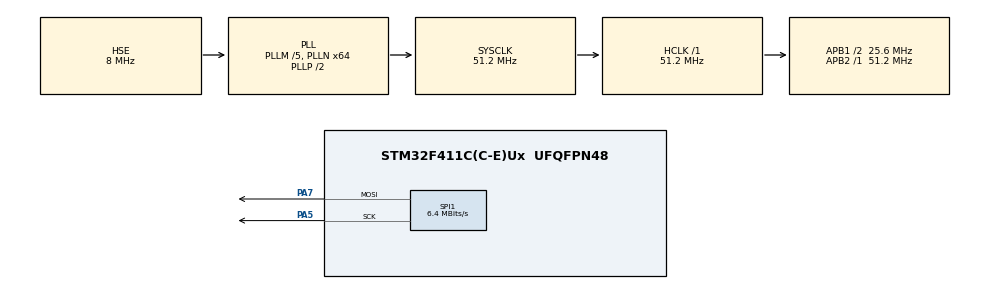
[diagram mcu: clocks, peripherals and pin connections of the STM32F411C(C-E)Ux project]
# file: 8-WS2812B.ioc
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Mcu.Family=STM32F4
Mcu.Name=STM32F411C(C-E)Ux
Mcu.Package=UFQFPN48
NVIC.PriorityGroup=NVIC_PRIORITYGROUP_4
PA13.Mode=Serial-Wire
PA13.Signal=SYS_JTMS-SWDIO
PA14.Mode=Serial-Wire
PA14.Signal=SYS_JTCK-SWCLK
PA5.Mode=TX_Only_Simplex_Unidirect_Master
PA5.Signal=SPI1_SCK
PA7.Mode=TX_Only_Simplex_Unidirect_Master
PA7.Signal=SPI1_MOSI
PC14-OSC32_IN.Mode=LSE-External-Oscillator
PC14-OSC32_IN.Signal=RCC_OSC32_IN
PC15-OSC32_OUT.Mode=LSE-External-Oscillator
PC15-OSC32_OUT.Signal=RCC_OSC32_OUT
PH0\ -\ OSC_IN.Mode=HSE-External-Oscillator
PH0\ -\ OSC_IN.Signal=RCC_OSC_IN
PH1\ -\ OSC_OUT.Mode=HSE-External-Oscillator
PH1\ -\ OSC_OUT.Signal=RCC_OSC_OUT
ProjectManager.HeapSize=0x200
ProjectManager.StackSize=0x400
ProjectManager.TargetToolchain=SW4STM32
RCC.48MHZClocksFreq_Value=25600000
RCC.AHBFreq_Value=51200000
RCC.APB1CLKDivider=RCC_HCLK_DIV2
RCC.APB1Freq_Value=25600000
RCC.APB1TimFreq_Value=51200000
RCC.APB2Freq_Value=51200000
RCC.APB2TimFreq_Value=51200000
RCC.CortexFreq_Value=51200000
RCC.HCLKFreq_Value=51200000
RCC.HSE_VALUE=8000000
RCC.HSI_VALUE=16000000
RCC.PLLM=5
RCC.PLLN=64
RCC.PLLSourceVirtual=RCC_PLLSOURCE_HSE
RCC.SYSCLKFreq_VALUE=51200000
RCC.SYSCLKSource=RCC_SYSCLKSOURCE_PLLCLK
RCC.VCOOutputFreq_Value=102400000
SPI1.BaudRatePrescaler=SPI_BAUDRATEPRESCALER_8
SPI1.CLKPolarity=SPI_POLARITY_LOW
SPI1.CalculateBaudRate=6.4 MBits/s
SPI1.DataSize=SPI_DATASIZE_8BIT
SPI1.Mode=SPI_MODE_MASTER
board=8-WS2812B

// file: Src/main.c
/**
 ******************************************************************************
 * File Name          : main.c
 * Description        : Main program body
 ******************************************************************************
 *
 * COPYRIGHT(c) 2016 STMicroelectronics
 *
 * Redistribution and use in source and binary forms, with or without modification,
 * are permitted provided that the following conditions are met:
 *   1. Redistributions of source code must retain the above copyright notice,
 *      this list of conditions and the following disclaimer.
 *   2. Redistributions in binary form must reproduce the above copyright notice,
 *      this list of conditions and the following disclaimer in the documentation
 *      and/or other materials provided with the distribution.
 *   3. Neither the name of STMicroelectronics nor the names of its contributors
 *      may be used to endorse or promote products derived from this software
 *      without specific prior written permission.
 *
 * THIS SOFTWARE IS PROVIDED BY THE COPYRIGHT HOLDERS AND CONTRIBUTORS "AS IS"
 * AND ANY EXPRESS OR IMPLIED WARRANTIES, INCLUDING, BUT NOT LIMITED TO, THE
 * IMPLIED WARRANTIES OF MERCHANTABILITY AND FITNESS FOR A PARTICULAR PURPOSE ARE
 * DISCLAIMED. IN NO EVENT SHALL THE COPYRIGHT HOLDER OR CONTRIBUTORS BE LIABLE
 * FOR ANY DIRECT, INDIRECT, INCIDENTAL, SPECIAL, EXEMPLARY, OR CONSEQUENTIAL
 * DAMAGES (INCLUDING, BUT NOT LIMITED TO, PROCUREMENT OF SUBSTITUTE GOODS OR
 * SERVICES; LOSS OF USE, DATA, OR PROFITS; OR BUSINESS INTERRUPTION) HOWEVER
 * CAUSED AND ON ANY THEORY OF LIABILITY, WHETHER IN CONTRACT, STRICT LIABILITY,
 * OR TORT (INCLUDING NEGLIGENCE OR OTHERWISE) ARISING IN ANY WAY OUT OF THE USE
 * OF THIS SOFTWARE, EVEN IF ADVISED OF THE POSSIBILITY OF SUCH DAMAGE.
 *
 ******************************************************************************
 */
#include "stm32f4xx_hal.h"
#include "spi.h"
#include "gpio.h"

/* USER CODE BEGIN Includes */
#include "ws2812b.h"
#include "lighting.h"
/* USER CODE END Includes */

/* USER CODE BEGIN PV */
/* Private variables ---------------------------------------------------------*/

/* USER CODE END PV */

void SystemClock_Config(void);

/* USER CODE BEGIN PFP */
/* Private function prototypes -----------------------------------------------*/

/* USER CODE END PFP */

int main(void) {

	/* MCU Configuration----------------------------------------------------------*/

	/* Reset of all peripherals, Initializes the Flash interface and the Systick. */
	HAL_Init();

	/* Configure the system clock */
	SystemClock_Config();

	/* Initialize all configured peripherals */
	MX_GPIO_Init();
	MX_SPI1_Init();

	/* USER CODE BEGIN 2 */
	ws2812b_config led_strip_c = ws2812b_init(&hspi1, 30);
	lighting_config l_c = lighting_init(30);

	lighting_hsv from_color, to_color;

	from_color.hue = 240;
	from_color.value = 0.5;

	to_color.hue = 360;
	to_color.value = 0.5;
	/* USER CODE END 2 */

	/* Infinite loop */
	while (1) {

		/* USER CODE BEGIN 3 */
		for (double i = 0; i < 2; i += 0.01) {
			double j;
			if (i > 1)
				j = 2 - i;
			else
				j = i;

			from_color.saturation = j;
			to_color.saturation = j;

			lighting_draw_gradient_hsv(&l_c, 0, 30, from_color, to_color);
			lighting_update_ws2812b(&l_c, &led_strip_c);
			ws2812b_refresh(&led_strip_c);
			HAL_Delay(20);
		}

		double tmp;
		tmp = from_color.hue;
		from_color.hue = to_color.hue;
		to_color.hue = tmp;
	}
	/* USER CODE END 3 */

}

/** System Clock Configuration
 */
void SystemClock_Config(void) {

	RCC_OscInitTypeDef RCC_OscInitStruct;
	RCC_ClkInitTypeDef RCC_ClkInitStruct;

	__HAL_RCC_PWR_CLK_ENABLE()
	;

	__HAL_PWR_VOLTAGESCALING_CONFIG(PWR_REGULATOR_VOLTAGE_SCALE1);

	RCC_OscInitStruct.OscillatorType = RCC_OSCILLATORTYPE_HSE;
	RCC_OscInitStruct.HSEState = RCC_HSE_ON;
	RCC_OscInitStruct.PLL.PLLState = RCC_PLL_ON;
	RCC_OscInitStruct.PLL.PLLSource = RCC_PLLSOURCE_HSE;
	RCC_OscInitStruct.PLL.PLLM = 5;
	RCC_OscInitStruct.PLL.PLLN = 64;
	RCC_OscInitStruct.PLL.PLLP = RCC_PLLP_DIV2;
	RCC_OscInitStruct.PLL.PLLQ = 4;
	HAL_RCC_OscConfig(&RCC_OscInitStruct);

	RCC_ClkInitStruct.ClockType = RCC_CLOCKTYPE_HCLK | RCC_CLOCKTYPE_SYSCLK
			| RCC_CLOCKTYPE_PCLK1 | RCC_CLOCKTYPE_PCLK2;
	RCC_ClkInitStruct.SYSCLKSource = RCC_SYSCLKSOURCE_PLLCLK;
	RCC_ClkInitStruct.AHBCLKDivider = RCC_SYSCLK_DIV1;
	RCC_ClkInitStruct.APB1CLKDivider = RCC_HCLK_DIV2;
	RCC_ClkInitStruct.APB2CLKDivider = RCC_HCLK_DIV1;
	HAL_RCC_ClockConfig(&RCC_ClkInitStruct, FLASH_LATENCY_1);

	HAL_SYSTICK_Config(HAL_RCC_GetHCLKFreq() / 1000);

	HAL_SYSTICK_CLKSourceConfig(SYSTICK_CLKSOURCE_HCLK);

	/* SysTick_IRQn interrupt configuration */
	HAL_NVIC_SetPriority(SysTick_IRQn, 0, 0);
}

/************************ (C) COPYRIGHT STMicroelectronics *****END OF FILE****/
